AUTOSAR XML (schema 314)
package /ComponentType
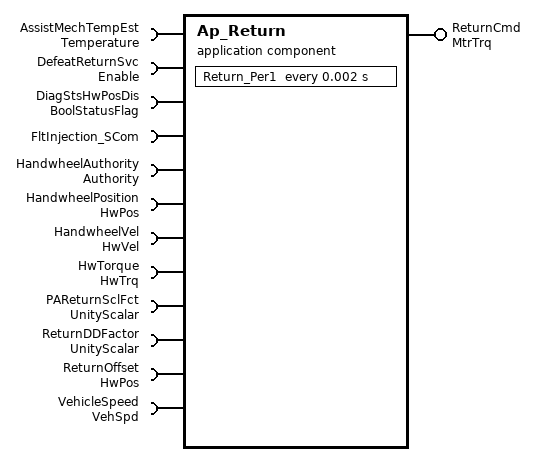
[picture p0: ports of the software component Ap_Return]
  application software component type Ap_Return
    provide port ReturnCmd: unqueued-sender-com-spec{data-element=MtrNm_f32, can-invalidate=false, init-value=D_ZERO_ULS_F32}, provided-interface=MtrTrq
    12 x require port:
      AssistMechTempEst: unqueued-receiver-com-spec{data-element=DegC_f32, init-value=D_ZERO_ULS_F32}, required-interface=Temperature
      DefeatReturnSvc: unqueued-receiver-com-spec{data-element=Cnt_lgc, init-value=D_FALSE_CNT_LGC}, required-interface=Enable
      DiagStsHwPosDis: unqueued-receiver-com-spec{data-element=Cnt_lgc, init-value=D_FALSE_CNT_LGC}, required-interface=BoolStatusFlag
      FltInjection_SCom: client-com-spec=FltInjection, required-interface=FltInjection_SCom
      HandwheelAuthority: unqueued-receiver-com-spec{data-element=Uls_f32, init-value=D_ZERO_ULS_F32}, required-interface=Authority
      HandwheelPosition: unqueued-receiver-com-spec{data-element=HwDeg_f32, init-value=D_ZERO_ULS_F32}, required-interface=HwPos
      HandwheelVel: unqueued-receiver-com-spec{data-element=HwRadpS_f32, init-value=D_FLOATZERO_ULS_F32}, required-interface=HwVel
      HwTorque: unqueued-receiver-com-spec{data-element=HwNm_f32, init-value=D_ZERO_ULS_F32}, required-interface=HwTrq
      PAReturnSclFct: unqueued-receiver-com-spec{data-element=Uls_f32, init-value=D_ONE_ULS_F32}, required-interface=UnityScalar
      ReturnDDFactor: unqueued-receiver-com-spec{data-element=Uls_f32, init-value=D_ONE_ULS_F32}, required-interface=UnityScalar
      ReturnOffset: unqueued-receiver-com-spec{data-element=HwDeg_f32, init-value=D_ZERO_ULS_F32}, required-interface=HwPos
      VehicleSpeed: unqueued-receiver-com-spec{data-element=Kph_f32, init-value=D_FLOATZERO_ULS_F32}, required-interface=VehSpd
  internal behavior Ap_Return_InternalBehavior: component=Ap_Return
    timing event TMT_Return_Per1: start-on-event=Return_Per1, period=0.002
    port-api-options:
      enable-take-address=false, indirect-api=false, port=AssistMechTempEst
      enable-take-address=false, indirect-api=false, port=DefeatReturnSvc
      enable-take-address=false, indirect-api=false, port=DiagStsHwPosDis
      enable-take-address=false, indirect-api=false, port=FltInjection_SCom
      enable-take-address=false, indirect-api=false, port=HandwheelAuthority
      enable-take-address=false, indirect-api=false, port=HandwheelPosition
      enable-take-address=false, indirect-api=false, port=HandwheelVel
      enable-take-address=false, indirect-api=false, port=HwTorque
      enable-take-address=false, indirect-api=false, port=PAReturnSclFct
      enable-take-address=false, indirect-api=false, port=ReturnCmd
      enable-take-address=false, indirect-api=false, port=ReturnDDFactor
      enable-take-address=false, indirect-api=false, port=ReturnOffset
      enable-take-address=false, indirect-api=false, port=VehicleSpeed
    runnable Return_Per1
      11 x data read access:
        READ_AssistMechTempEst_DegC_f32: data-element=AssistMechTempEst.DegC_f32
        READ_DefeatReturnSvc_Cnt_lgc: data-element=DefeatReturnSvc.Cnt_lgc
        READ_DiagStsHwPosDis_Cnt_lgc: data-element=DiagStsHwPosDis.Cnt_lgc
        READ_HandwheelAuthority_Uls_f32: data-element=HandwheelAuthority.Uls_f32
        READ_HandwheelPosition_HwDeg_f32: data-element=HandwheelPosition.HwDeg_f32
        READ_HandwheelVel_HwRadpS_f32: data-element=HandwheelVel.HwRadpS_f32
        READ_HwTorque_HwNm_f32: data-element=HwTorque.HwNm_f32
        READ_PAReturnSclFct_Uls_f32: data-element=PAReturnSclFct.Uls_f32
        READ_ReturnDDFactor_Uls_f32: data-element=ReturnDDFactor.Uls_f32
        READ_ReturnOffset_HwDeg_f32: data-element=ReturnOffset.HwDeg_f32
        READ_VehicleSpeed_Kph_f32: data-element=VehicleSpeed.Kph_f32
      data write access WRITE_ReturnCmd_MtrNm_f32: data-element=ReturnCmd.MtrNm_f32
      sync call SC_FltInjection_SCom_FltInjection: operation=FltInjection_SCom.FltInjection, timeout=0
  swc implementation Ap_Return_Implementation: behavior=Ap_Return_InternalBehavior
    code-descriptors:
      code Code: type=SRC
